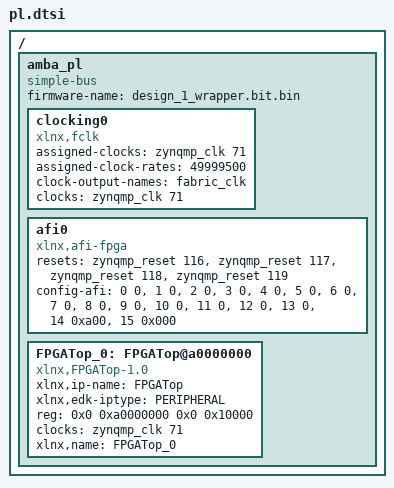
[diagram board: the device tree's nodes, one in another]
/ {
	amba_pl: amba_pl {
		ranges;
		compatible = "simple-bus";
		#address-cells = <2>;
		#size-cells = <2>;
		firmware-name = "design_1_wrapper.bit.bin";
		clocking0: clocking0 {
			compatible = "xlnx,fclk";
			status = "okay";
			assigned-clocks = <&zynqmp_clk 71>;
			assigned-clock-rates = <49999500>;
			#clock-cells = <0>;
			clock-output-names = "fabric_clk";
			clocks = <&zynqmp_clk 71>;
		};
		afi0: afi0 {
			status = "okay";
			compatible = "xlnx,afi-fpga";
			resets = <&zynqmp_reset 116>, <&zynqmp_reset 117>, <&zynqmp_reset 118>, <&zynqmp_reset 119>;
			config-afi = < 0 0>, <1 0>, <2 0>, <3 0>, <4 0>, <5 0>, <6 0>, <7 0>, <8 0>, <9 0>, <10 0>, <11 0>, <12 0>, <13 0>, <14 0xa00>, <15 0x000>;
		};
		FPGATop_0: FPGATop@a0000000 {
			compatible = "xlnx,FPGATop-1.0";
			status = "okay";
			clock-names = "aclk";
			xlnx,ip-name = "FPGATop";
			xlnx,edk-iptype = "PERIPHERAL";
			reg = <0x0 0xa0000000 0x0 0x10000>;
			clocks = <&zynqmp_clk 71>;
			xlnx,name = "FPGATop_0";
		};
	};
};
